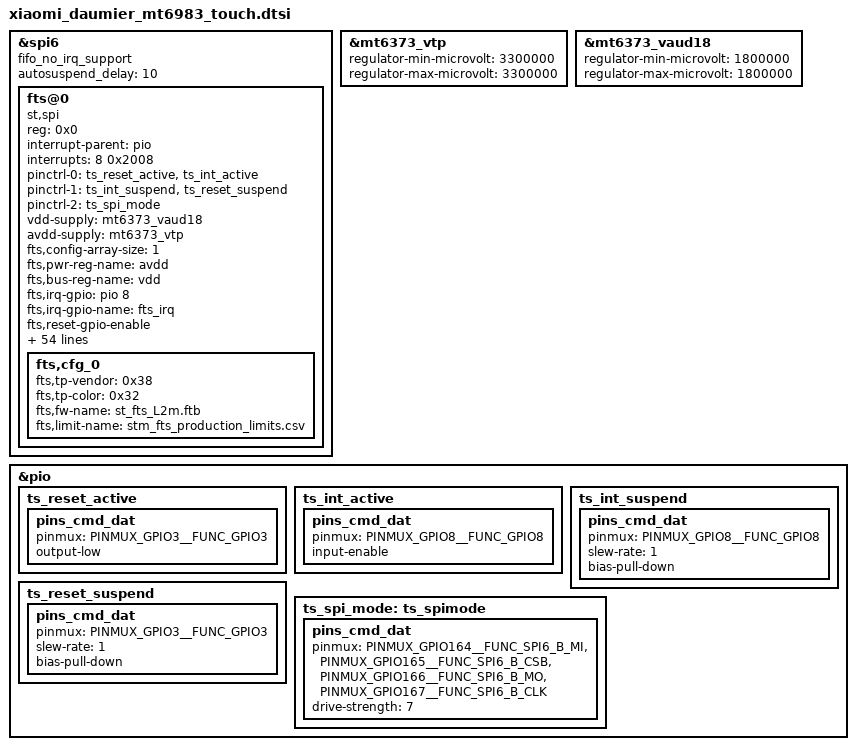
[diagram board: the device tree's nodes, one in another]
// SPDX-License-Identifier: (GPL-2.0 OR MIT)
/*
 * Copyright (C) 2020 MediaTek Inc.
 */

/* TOUCH start */

&spi6 {
	status = "okay";
	fifo_no_irq_support;
	autosuspend_delay = <10>;
	#address-cells = <1>;
	#size-cells = <0>;

	fts@0 {
		status = "ok";
		compatible = "st,spi";
		reg = <0x0>;
		interrupt-parent = <&pio>;
		interrupts = <8 0x2008>;
		pinctrl-names = "pmx_ts_active", "pmx_ts_suspend", "pmx_ts_spi_mode";
		pinctrl-0 = <&ts_reset_active &ts_int_active>;
		pinctrl-1 = <&ts_int_suspend &ts_reset_suspend>;
		pinctrl-2 = <&ts_spi_mode>;
		vdd-supply = <&mt6373_vaud18>;
		avdd-supply = <&mt6373_vtp>;
		fts,config-array-size = <1>;
		fts,pwr-reg-name = "avdd";
		fts,bus-reg-name = "vdd";
		fts,irq-gpio = <&pio 8 0x0>;
		fts,irq-gpio-name = "fts_irq";
		fts,reset-gpio-enable;
		fts,reset-gpio = <&pio 3 0x0>;
		fts,reset-gpio-name = "fts_rst";
		fts,irq-flags = <0x2008>;/* 1:rising, 2:falling;*/
		fts,x-max = <14400>;/*Super resolution*/
		fts,y-max = <32000>;/*Super resolution*/
		fts,screen_x = <1440>;
		fts,screen_y = <3200>;

		fts,support-fod = <1>;
		fts,fod-lx = <5870>;
		fts,fod-ly = <23460>;
		fts,fod-x-size = <2660>;
		fts,fod-y-size = <2660>;

		fts,support-super-resolution = <1>;
		spi-max-frequency = <12000000>;

		boost_support;
		game_cpumask = <0x0f>;
		game_irq_boost_target = <700000>;
		fts,default-fw-name = "st_fts_L2m.ftb";
		fts,thp-fw-name = "st_fts_L2m_thp.ftb";
		fts,non-curved-display = <1>;
		fts,touch-follow-performance-def = <3>;
		fts,touch-tap-sensitivity-def = <4>;
		fts,touch-aim-sensitivity-def = <3>;
		fts,touch-tap-stability-def = <3>;
		fts,cornerfilter-area-step1 = <150>;
		fts,cornerfilter-area-step2 = <280>;
		fts,cornerfilter-area-step3 = <400>;
		fts,touch-deadzone-filter-ver = <2 0 0 0 0 0 0 0
						 2 1 0 0 0 0 0 0
						 2 2 0 0 0 3199 0 0
						 2 3 1439 0 1439 3199 0 0>;
		fts,touch-deadzone-filter-hor = <2 0 0 0 0 0 0 0
						 2 1 0 0 0 0 0 0
						 2 2 0 0 0 0 0 0
						 2 3 0 0 0 0 0 0>;
		fts,touch-edgezone-filter-ver = <1 0 0 0 0 0 0 0
						 1 1 0 0 0 0 0 0
						 1 2 0 0 60 3199 0 0
						 1 3 1379 0 1439 3199 0 0>;
		fts,touch-edgezone-filter-hor = <1 0 0 0 1439 60 0 0
						 1 1 0 3139 1439 3199 0 0
						 1 2 0 0 60 3199 0 0
						 1 3 1379 0 1439 3199 0 0>;
		fts,touch-cornerzone-filter-ver = <0 0 0 0 0 0 0 0
						   0 1 0 0 0 0 0 0
						   0 2 0 2799 250 3199 0 0
						   0 3 1189 2799 1439 3199 0 0>;
		fts,touch-cornerzone-filter-hor1 = <0 0 0 0 280 280 0 0
						    0 1 0 0 0 0 0 0
						    0 2 0 2919 280 3199 0 0
						    0 3 0 0 0 0 0 0>;
		fts,touch-cornerzone-filter-hor2 = <0 0 0 0 0 0 0 0
						    0 1 1159 0 1439 280 0 0
						    0 2 0 0 0 0 0 0
						    0 3 1159 2919 1439 3199 0 0>;
		fts,touch-normal-edgezone-filter-hor = <1 0 0 0 1439 40 0 0
							1 1 0 3159 1439 3199 0 0
							1 2 0 0 40 3199 0 0
							1 3 1399 0 1439 3199 0 0>;
		fts,touch-normal-cornerzone-filter-hor1 = <0 0 0 0 280 280 0 0
							   0 1 0 0 0 0 0 0
							   0 2 0 2919 280 3199 0 0
							   0 3 0 0 0 0 0 0>;
		fts,touch-normal-cornerzone-filter-hor2 = <0 0 0 0 0 0 0 0
							   0 1 1159 0 1439 280 0 0
							   0 2 0 0 0 0 0 0
							   0 3 1159 2919 1439 3199 0 0>;
		fts,touch-follow-performance = <10 15 1
						8 15 1
						6 15 1
						4 15 1
						2 15 1>;
		fts,touch-tap-sensitivity = <160 150 140 120 100>;
		fts,touch-aim-sensitivity = <10 8 6 5 4>;
		fts,touch-tap-stability = <11 16 20 22 28>;
		fts,touch-expert-array = <6 15 1 120 6 20
					  2 15 1 120 5 20
					  4 15 1 120 4 20>;
		fts,cfg_0 {
			fts,tp-vendor = <0x38>;
			fts,tp-color = <0x32>;
			fts,fw-name = "st_fts_L2m.ftb";
			fts,limit-name = "stm_fts_production_limits.csv";
		};
	};
};

&mt6373_vtp {
	regulator-min-microvolt = <3300000>;
	regulator-max-microvolt = <3300000>;
};

&mt6373_vaud18 {
	regulator-min-microvolt = <1800000>;
	regulator-max-microvolt = <1800000>;
};

&pio {
	ts_reset_active: ts_reset_active {
		pins_cmd_dat {
			pinmux = <PINMUX_GPIO3__FUNC_GPIO3>;
			output-low;
		};
	};
	ts_int_active: ts_int_active {
		pins_cmd_dat {
			pinmux = <PINMUX_GPIO8__FUNC_GPIO8>;
			input-enable;
		};
	};
	ts_int_suspend: ts_int_suspend {
		pins_cmd_dat {
			pinmux = <PINMUX_GPIO8__FUNC_GPIO8>;
			slew-rate = <1>;
			bias-pull-down;
		};
	};
	ts_reset_suspend: ts_reset_suspend {
		pins_cmd_dat {
			pinmux = <PINMUX_GPIO3__FUNC_GPIO3>;
			slew-rate = <1>;
			bias-pull-down;
		};
	};
	ts_spi_mode: ts_spimode {
		pins_cmd_dat {
			pinmux = <PINMUX_GPIO164__FUNC_SPI6_B_MI>,
				<PINMUX_GPIO165__FUNC_SPI6_B_CSB>,
				<PINMUX_GPIO166__FUNC_SPI6_B_MO>,
				<PINMUX_GPIO167__FUNC_SPI6_B_CLK>;
			drive-strength = <7>;
		};
	};

};
/* TOUCH end */
